# PIC18LF8520 register map
Vendor: Microchip
Architecture 18xxxx. Special function registers and configuration words.
Registers are 8-bit, read-write, no defined reset value unless marked. A register's access mark holds for its fields unless they carry their own. Addresses are absolute, and some are shared; only a register's first bit layout is shown; lines under a group give offsets from that group; [hi:lo] are bit positions; {n}, {i} and the like mark numbered series; 'fields as' and 'values as' point back to an identical list; <NAME> marks a mode.

## Further device data
pins=1: RH2/A18; 2: RH3/A19; 3: RE1/WR/AD9; 4: RE0/RD/AD8; 5: RG0/CCP3; 6: RG1/TX2/CK2; 7: RG2/RX2/DT2; 8: RG3/CCP4; 9: MCLR/Vpp; 10: RG4/CCP5; 11: Vss; 12: Vdd; 13: RF7/SS; 14: RF6/AN11; 15: RF5/AN10/CVref; 16: RF4/AN9; 17: RF3/AN8; 18: RF2/AN7/C1OUT; 19: RH7/AN15; 20: RH6/AN14; 21: RH5/AN13; 22: RH4/AN12; 23: RF1/AN6/C2OUT; 24: RF0/AN5; 25: Avdd; 26: Avss; 27: RA3/AN3/Vref+; 28: RA2/AN2/Vref-; 29: RA1/AN1; 30: RA0/AN0; 31: Vss; 32: Vdd; 33: RA5/AN4/LVDIN; 34: RA4/T0CKI; 35: RC1/T1OSI/CCP2; 36: RC0/T1OSO/T13CKI; 37: RC6/TX1/CK1; 38: RC7/RX1/DT1; 39: RJ4/BA0; 40: RJ5/CE; 41: RJ6/LB; 42: RJ7/UB; 43: RC2/CCP1; 44: RC3/SCK/SCL; 45: RC4/SDI/SDA; 46: RC5/SDO; 47: RB7/KBI3/PGD; 48: Vdd; 49: OSC1/CLKI; 50: OSC2/CLKO/RA6; 51: Vss; 52: RB6/KBI2/PGC; 53: RB5/KBI1/PGM; 54: RB4/KBI0; 55: RB3/INT3/CCP2; 56: RB2/INT2; 57: RB1/INT1; 58: RB0/INT0; 59: RJ3/WRH; 60: RJ2/WRL; 61: RJ1/OE; 62: RJ0/ALE; 63: RD7/PSP7/AD7; 64: RD6/PSP6/AD6; 65: RD5/PSP5/AD5; 66: RD4/PSP4/AD4; 67: RD3/PSP3/AD3; 68: RD2/PSP2/AD2; 69: RD1/PSP1/AD1; 70: Vss; 71: Vdd; 72: RD0/PSP0/AD0; 73: RE7/CCP2/AD15; 74: RE6/AD14; 75: RE5/AD13; 76: RE4/AD12; 77: RE3/AD11; 78: RE2/CS/AD10; 79: RH0/A16; 80: RH1/A17

## CONFIG — Configuration words, addresses in ProgramSpace
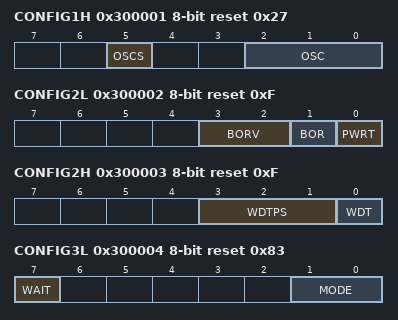
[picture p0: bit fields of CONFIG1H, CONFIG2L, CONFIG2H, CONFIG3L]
0x300001 CONFIG1H reset 0x27
  [5] OSCS — Oscillator System Clock Switch Enable bit
    1=OFF (Oscillator system clock switch option is disabled (main oscillator is source)); 0=ON (Timer1 Oscillator system clock switch option is enabled (oscillator switching is enabled))
  [2:0] OSC — Oscillator Selection bits
    7=RCIO (RC oscillator w/ OSC2 configured as RA6); 6=HSPLL (HS oscillator with PLL enabled; clock frequency = (4 x FOSC)); 5=ECIO (EC oscillator w/ OSC2 configured as RA6); 4=EC (EC oscillator w/ OSC2 configured as divide-by-4 clock output); 3=RC (RC oscillator w/ OSC2 configured as divide-by-4 clock output); 2=HS (HS oscillator); 1=XT (XT oscillator); 0=LP (LP oscillator)
0x300002 CONFIG2L reset 0xF
  [3:2] BORV — Brown-out Reset Voltage bits
    3=VBOR set to 2.5V; 2=VBOR set to 2.7V; 1=VBOR set to 4.2V; 0=VBOR set to 4.5V
  [1] BOR — Brown-out Reset Enable bit
    1=ON (Brown-out Reset enabled); 0=OFF (Brown-out Reset disabled)
  [0] PWRT — Power-up Timer Enable bit
    1=OFF (PWRT disabled); 0=ON (PWRT enabled)
0x300003 CONFIG2H reset 0xF
  [3:1] WDTPS — Watchdog Timer Postscale Select bits
    7=1:128; 6=1:64; 5=1:32; 4=1:16; 3=1:8; 2=1:4; 1=1:2; 0=1:1
  [0] WDT — Watchdog Timer Enable bit
    1=ON (WDT enabled); 0=OFF (WDT disabled (control is placed on the SWDTEN bit))
0x300004 CONFIG3L reset 0x83
  [7] WAIT — External Bus Data Wait Enable bit
    1=OFF (Wait selections unavailable for table reads and table writes); 0=ON (Wait selections for table reads and table writes are determined by the WAIT1:WAIT0 bits (MEMCOM<5:4>))
  [1:0] MODE — Processor Mode Select bits
    3=MC (Microcontroller mode); 2=MP (Microprocessor mode); 1=MPB (Microprocessor with Boot Block mode); 0=EM (Extended Microcontroller mode)
0x300005 CONFIG3H reset 0x3
  [0] CCP2MUX — CCP2 Mux bit
    1=ON (CCP2 input/output is multiplexed with RC1); 0=OFF (CCP2 is multiplexed with RB3 in Extended Microcontroller, Microprocessor or Microprocessor with Boot Block mode. Or with RE7 in Microcontroller mode.)
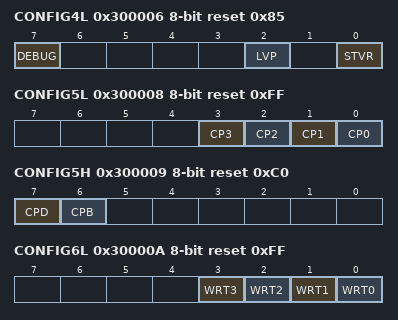
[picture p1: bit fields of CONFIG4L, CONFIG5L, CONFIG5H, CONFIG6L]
0x300006 CONFIG4L reset 0x85
  [7] DEBUG — Background Debugger Enable bit
    1=OFF (Background debugger disabled. RB6 and RB7 configured as general purpose I/O pins.); 0=ON (Background debugger enabled. RB6 and RB7 are dedicated to In-Circuit Debug.)
  [2] LVP — Low-Voltage ICSP Enable bit
    1=ON (Low-voltage ICSP enabled); 0=OFF (Low-voltage ICSP disabled)
  [0] STVR — Stack Full/Underflow Reset Enable bit
    1=ON (Stack full/underflow will cause Reset); 0=OFF (Stack full/underflow will not cause Reset)
0x300008 CONFIG5L reset 0xFF
  [3] CP3 — Code Protection bit
    1=OFF (Block 3 (006000-007FFFh) not code-protected); 0=ON (Block 3 (006000-007FFFh) code-protected)
  [2] CP2 — Code Protection bit
    1=OFF (Block 2 (004000-005FFFh) not code-protected); 0=ON (Block 2 (004000-005FFFh) code-protected)
  [1] CP1 — Code Protection bit
    1=OFF (Block 1 (002000-003FFFh) not code-protected); 0=ON (Block 1 (002000-003FFFh) code-protected)
  [0] CP0 — Code Protection bit
    1=OFF (Block 0 (000800-001FFFh) not code-protected); 0=ON (Block 0 (000800-001FFFh) code-protected)
0x300009 CONFIG5H reset 0xC0
  [7] CPD — Data EEPROM Code Protection bit
    1=OFF (Data EEPROM not code-protected); 0=ON (Data EEPROM code-protected)
  [6] CPB — Boot Block Code Protection bit
    1=OFF (Boot Block (000000-0007FFh) not code-protected); 0=ON (Boot Block (000000-0007FFh) code-protected)
0x30000A CONFIG6L reset 0xFF
  [3] WRT3 — Write Protection bit
    1=OFF (Block 3 (006000-007FFFh) not write-protected); 0=ON (Block 3 (006000-007FFFh) write-protected)
  [2] WRT2 — Write Protection bit
    1=OFF (Block 2 (004000-005FFFh) not write-protected); 0=ON (Block 2 (004000-005FFFh) write-protected)
  [1] WRT1 — Write Protection bit
    1=OFF (Block 1 (002000-003FFFh) not write-protected); 0=ON (Block 1 (002000-003FFFh) write-protected)
  [0] WRT0 — Write Protection bit
    1=OFF (Block 0 (000800-001FFFh) not write-protected); 0=ON (Block 0 (000800-001FFFh) write-protected)
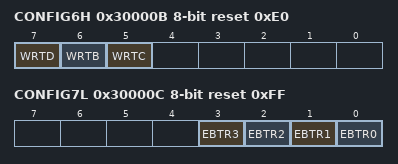
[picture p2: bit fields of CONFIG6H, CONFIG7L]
0x30000B CONFIG6H reset 0xE0
  [7] WRTD — Data EEPROM Write Protection bit
    1=OFF (Data EEPROM not write-protected); 0=ON (Data EEPROM write-protected)
  [6] WRTB — Boot Block Write Protection bit
    1=OFF (Boot Block (000000-0007FFh) not write-protected); 0=ON (Boot Block (000000-0007FFh) write-protected)
  [5] WRTC — Configuration Register Write Protection bit
    1=OFF (Configuration registers (300000-3000FFh) not write-protected); 0=ON (Configuration registers (300000-3000FFh) write-protected)
0x30000C CONFIG7L reset 0xFF
  [3] EBTR3 — Table Read Protection bit
    1=OFF (Block 3 (006000-007FFFh) not protected from table reads executed in other blocks); 0=ON (Block 3 (006000-007FFFh) protected from table reads executed in other blocks)
  [2] EBTR2 — Table Read Protection bit
    1=OFF (Block 2 (004000-005FFFh) not protected from table reads executed in other blocks); 0=ON (Block 2 (004000-005FFFh) protected from table reads executed in other blocks)
  [1] EBTR1 — Table Read Protection bit
    1=OFF (Block 1 (002000-003FFFh) not protected from table reads executed in other blocks); 0=ON (Block 1 (002000-003FFFh) protected from table reads executed in other blocks)
  [0] EBTR0 — Table Read Protection bit
    1=OFF (Block 0 (000800-001FFFh) not protected from table reads executed in other blocks); 0=ON (Block 0 (000800-001FFFh) protected from table reads executed in other blocks)
0x30000D CONFIG7H reset 0x40
  [6] EBTRB — Boot Block Table Read Protection bit
    1=OFF (Boot Block (000000-0007FFh) not protected from table reads executed in other blocks); 0=ON (Boot Block (000000-0007FFh) protected from table reads executed in other blocks)
